AUTOSAR XML (schema 4-3-1)
package /Component
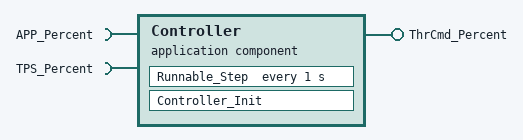
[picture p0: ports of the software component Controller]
  application sw component type Controller
    provide port ThrCmd_Percent: nonqueued-sender-com-spec{data-element=Value_4, init-value=0}, provided-interface=ThrCmd_Percent
    require port APP_Percent: nonqueued-receiver-com-spec{data-element=Value_2, init-value=0}, required-interface=APP_Percent
    require port TPS_Percent: nonqueued-receiver-com-spec{data-element=Value_6, init-value=0}, required-interface=TPS_Percent
    behavior test_IB: handle-termination-and-restart=NO-SUPPORT
      timing event Event_Runnable_Step: start-on-event=Runnable_Step, period=1
      runnable Controller_Init
      runnable Runnable_Step
        data-read-access:
          access IN_APP_Percent_Value_2: accessed-variable=APP_Percent.Value_2
          access IN_TPS_Percent_Value_6: accessed-variable=TPS_Percent.Value_6
        data-write-access:
          access OUT_ThrCmd_Percent_Value_4: accessed-variable=ThrCmd_Percent.Value_4
